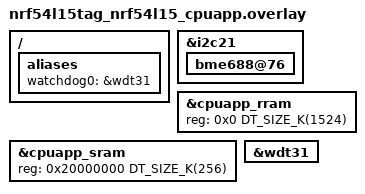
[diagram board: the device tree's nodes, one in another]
/*
 * Copyright (c) 2026 Nordic Semiconductor ASA
 *
 * SPDX-License-Identifier: LicenseRef-Nordic-5-Clause
 */

/ {
	aliases {
		/* Use watchdog wdt31 as the application watchdog */
		watchdog0 = &wdt31;
	};
};

/* BME688 (temperature pressure and humidity sensor) */
&i2c21 {
	bme688@76 {
		status = "okay";
	};
};

/* restore full RRAM and SRAM space - by default some parts are dedicated to FLRP */
&cpuapp_rram {
	reg = <0x0 DT_SIZE_K(1524)>;
};

&cpuapp_sram {
	reg = <0x20000000 DT_SIZE_K(256)>;
	ranges = <0x0 0x20000000 0x40000>;
};

&wdt31 {
	status = "okay";
};
